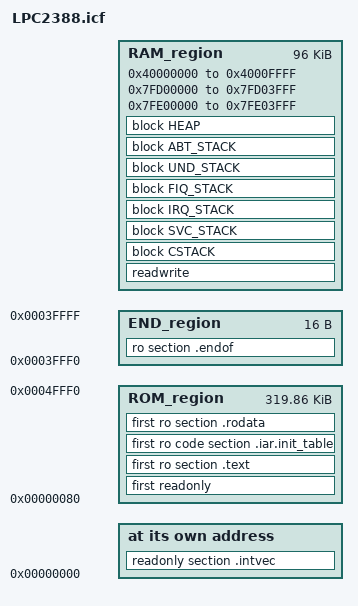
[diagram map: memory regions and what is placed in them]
/*###ICF### Section handled by ICF editor, don't touch! ****/
/*-Editor annotation file-*/
/* IcfEditorFile="$TOOLKIT_DIR$\config\ide\IcfEditor\a_v1_0.xml" */
/*-Specials-*/
define symbol __ICFEDIT_intvec_start__ = 0x0;
/*-Memory Regions-*/
define symbol __ICFEDIT_region_ROM_start__  = 0x80;
define symbol __ICFEDIT_region_ROM_end__    = 0x4FFF0;
define symbol __ICFEDIT_region_RAM_start__  = 0x40000000;
define symbol __ICFEDIT_region_RAM_end__    = 0x4000FFFF;
define symbol __ICFEDIT_region_RAM2_start__ = 0x7FD00000;
define symbol __ICFEDIT_region_RAM2_end__   = 0x7FD03FFF;
define symbol __ICFEDIT_region_RAM3_start__ = 0x7FE00000;
define symbol __ICFEDIT_region_RAM3_end__   = 0x7FE03FFF;
/*-Sizes-*/
define symbol __ICFEDIT_size_cstack__   = 0x1f00;
define symbol __ICFEDIT_size_svcstack__ = 0x100;
define symbol __ICFEDIT_size_irqstack__ = 0x100;
define symbol __ICFEDIT_size_fiqstack__ = 0x100;
define symbol __ICFEDIT_size_undstack__ = 0x100;
define symbol __ICFEDIT_size_abtstack__ = 0x100;
define symbol __ICFEDIT_size_heap__     = 0x0;
/**** End of ICF editor section. ###ICF###*/


define memory mem with size = 4G;
define region ROM_region   = mem:[from __ICFEDIT_region_ROM_start__   to __ICFEDIT_region_ROM_end__];
define region RAM_region   = mem:[from __ICFEDIT_region_RAM_start__   to __ICFEDIT_region_RAM_end__] | mem:[from __ICFEDIT_region_RAM2_start__   to __ICFEDIT_region_RAM2_end__] | mem:[from __ICFEDIT_region_RAM3_start__   to __ICFEDIT_region_RAM3_end__];

define symbol END_region_ROM_start__ = 0x3FFF0;
define symbol END_region_ROM_end__   = 0x3FFFF;
define region END_region   = mem:[from END_region_ROM_start__    to END_region_ROM_end__];



define block CSTACK    with alignment = 8, size = __ICFEDIT_size_cstack__   { };
define block SVC_STACK with alignment = 8, size = __ICFEDIT_size_svcstack__ { };
define block IRQ_STACK with alignment = 8, size = __ICFEDIT_size_irqstack__ { };
define block FIQ_STACK with alignment = 8, size = __ICFEDIT_size_fiqstack__ { };
define block UND_STACK with alignment = 8, size = __ICFEDIT_size_undstack__ { };
define block ABT_STACK with alignment = 8, size = __ICFEDIT_size_abtstack__ { };
define block HEAP      with alignment = 8, size = __ICFEDIT_size_heap__     { };



initialize by copy { readwrite };
do not initialize  { section .noinit };

place at address mem:__ICFEDIT_intvec_start__ { readonly section .intvec };




place in ROM_region   {first readonly };

place in ROM_region {first ro section .text};
place in ROM_region {first ro code section .iar.init_table};
place in ROM_region {first ro section .rodata};


place in END_region {ro section .endof};
keep { section .endof};

place in RAM_region   { readwrite,
                        block CSTACK, block SVC_STACK, block IRQ_STACK, block FIQ_STACK,
                        block UND_STACK, block ABT_STACK, block HEAP };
